AUTOSAR XML (schema 4-0-3)
package /ComponentTypes
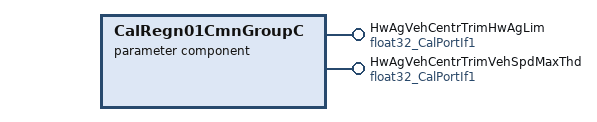
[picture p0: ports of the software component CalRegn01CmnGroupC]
  parameter sw component type CalRegn01CmnGroupC
    provide port HwAgVehCentrTrimHwAgLim: parameter-provide-com-spec{init-value=30, parameter=Val}, provided-interface=float32_CalPortIf1
    provide port HwAgVehCentrTrimVehSpdMaxThd: parameter-provide-com-spec{init-value=0, parameter=Val}, provided-interface=float32_CalPortIf1
